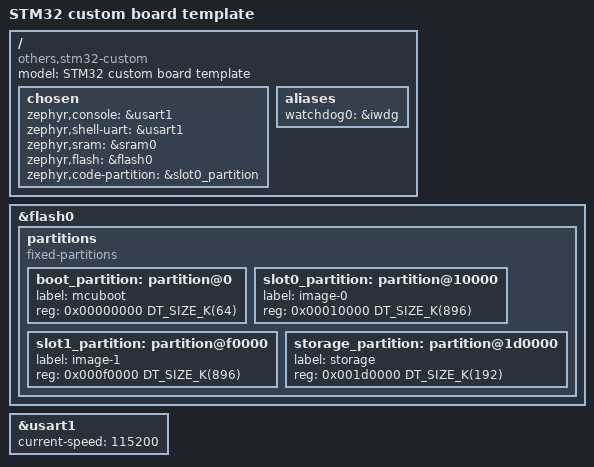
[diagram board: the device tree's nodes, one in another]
/*
 * SPDX-License-Identifier: Apache-2.0
 */

/dts-v1/;

#include <st/u5/stm32u5a9Xj.dtsi>
#include <st/u5/stm32u5a9njhxq-pinctrl.dtsi>

/ {
	model = "STM32 custom board template";
	compatible = "others,stm32-custom";

	chosen {
		zephyr,console = &usart1;
		zephyr,shell-uart = &usart1;
		zephyr,sram = &sram0;
		zephyr,flash = &flash0;
		zephyr,code-partition = &slot0_partition;
	};

	aliases {
		watchdog0 = &iwdg;
	};
};

&flash0 {
	partitions {
		compatible = "fixed-partitions";
		#address-cells = <1>;
		#size-cells = <1>;

		boot_partition: partition@0 {
			label = "mcuboot";
			reg = <0x00000000 DT_SIZE_K(64)>;
		};

		slot0_partition: partition@10000 {
			label = "image-0";
			reg = <0x00010000 DT_SIZE_K(896)>;
		};

		slot1_partition: partition@f0000 {
			label = "image-1";
			reg = <0x000f0000 DT_SIZE_K(896)>;
		};

		storage_partition: partition@1d0000 {
			label = "storage";
			reg = <0x001d0000 DT_SIZE_K(192)>;
		};
	};
};

&usart1 {
	status = "okay";
	current-speed = <115200>;
};
